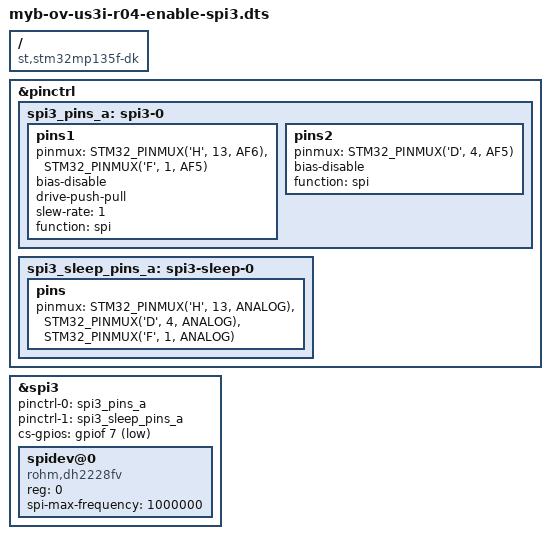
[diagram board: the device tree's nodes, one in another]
/dts-v1/;
/plugin/;

#include <dt-bindings/gpio/gpio.h>
#include <dt-bindings/pinctrl/stm32-pinfunc.h>

/ {
    compatible = "st,stm32mp135f-dk", "st,stm32mp135";

    fragment@0 {
        target = <&pinctrl>;
        __overlay__ {
            spi3_pins_a: spi3-0 {
                pins1 {
                    pinmux = <STM32_PINMUX('H', 13, AF6)>, /* SPI3_SCK */
                            <STM32_PINMUX('F', 1, AF5)>; /* SPI3_MOSI */
                    bias-disable;
                    drive-push-pull;
                    slew-rate = <1>;
                    function = "spi";
                };

                pins2 {
                    pinmux = <STM32_PINMUX('D', 4, AF5)>; /* SPI3_MISO */
                    bias-disable;
                    function = "spi";
                };
            };

            spi3_sleep_pins_a: spi3-sleep-0 {
                pins {
                    pinmux = <STM32_PINMUX('H', 13, ANALOG)>, /* SPI3_SCK */
                            <STM32_PINMUX('D', 4, ANALOG)>, /* SPI3_MISO */
                            <STM32_PINMUX('F', 1, ANALOG)>; /* SPI3_MOSI */
                };
            };
        };
    };

    fragment@1 {
        target = <&spi3>;
        __overlay__ {
            pinctrl-names = "default";
            pinctrl-0 = <&spi3_pins_a>;
            pinctrl-1 = <&spi3_sleep_pins_a>;
            status = "okay";
            cs-gpios = <&gpiof 7 GPIO_ACTIVE_LOW>;  /* Chip select GPIO */
            
            spidev@0 {
                compatible = "rohm,dh2228fv";
                reg = <0>;  /* Chip Select 0 */
                spi-max-frequency = <1000000>;
                status = "okay";
            };
        };
    };
};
